# MSP432E411Y register map
Vendor: Texas Instruments; File version: 3.200
CPU: CM4 r1p2, little endian, no MPU, no FPU, 0x3 interrupt priority bits, 0x0 interrupts
Registers are 32-bit, read-write, no defined reset value unless marked. A register's access mark holds for its fields unless they carry their own. Offsets are from the block's base; [hi:lo] are bit positions; {n}, {i} and the like mark numbered series.

## TIMER0 — Register map for TIMER0 peripheral
Base 0x40030000; register names take the prefix TIMER0
0x00 CFG — GPTM Configuration
  [2:0] TIMER_CFG
    0=TIMER_CFG_32_BIT_TIMER (For a 16/32-bit timer, this value selects the 32-bit timer configuration); 1=TIMER_CFG_32_BIT_RTC (For a 16/32-bit timer, this value selects the 32-bit real-time clock (RTC) counter configuration); 4=TIMER_CFG_16_BIT (For a 16/32-bit timer, this value selects the 16-bit timer configuration)
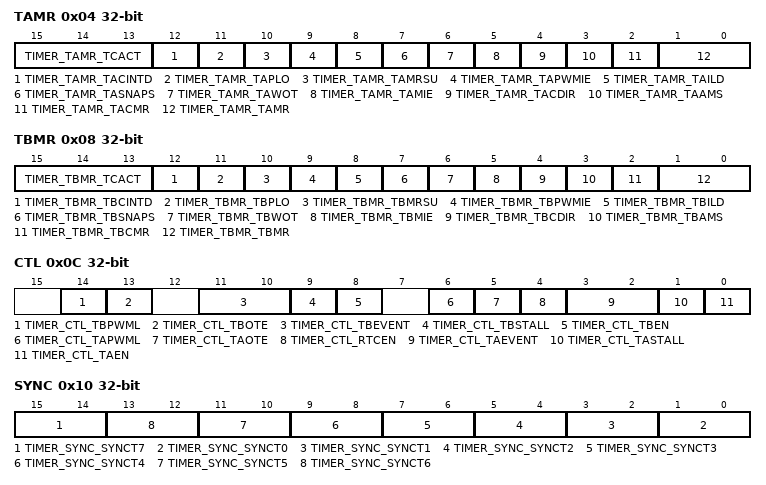
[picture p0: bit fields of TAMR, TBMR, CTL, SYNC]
0x04 TAMR — GPTM Timer A Mode
  [15:13] TIMER_TAMR_TCACT — Timer Compare Action Select
    0=TIMER_TAMR_TCACT_NONE (Disable compare operations); 1=TIMER_TAMR_TCACT_TOGGLE (Toggle State on Time-Out); 2=TIMER_TAMR_TCACT_CLRTO (Clear CCP on Time-Out); 3=TIMER_TAMR_TCACT_SETTO (Set CCP on Time-Out); 4=TIMER_TAMR_TCACT_SETTOGTO (Set CCP immediately and toggle on Time-Out); 5=TIMER_TAMR_TCACT_CLRTOGTO (Clear CCP immediately and toggle on Time-Out); 6=TIMER_TAMR_TCACT_SETCLRTO (Set CCP immediately and clear on Time-Out); 7=TIMER_TAMR_TCACT_CLRSETTO (Clear CCP immediately and set on Time-Out)
  [12] TIMER_TAMR_TACINTD — One-shot/Periodic Interrupt Disable
  [11] TIMER_TAMR_TAPLO — GPTM Timer A PWM Legacy Operation
  [10] TIMER_TAMR_TAMRSU — GPTM Timer A Match Register Update
  [9] TIMER_TAMR_TAPWMIE — GPTM Timer A PWM Interrupt Enable
  [8] TIMER_TAMR_TAILD — GPTM Timer A Interval Load Write
  [7] TIMER_TAMR_TASNAPS — GPTM Timer A Snap-Shot Mode
  [6] TIMER_TAMR_TAWOT — GPTM Timer A Wait-on-Trigger
  [5] TIMER_TAMR_TAMIE — GPTM Timer A Match Interrupt Enable
  [4] TIMER_TAMR_TACDIR — GPTM Timer A Count Direction
  [3] TIMER_TAMR_TAAMS — GPTM Timer A Alternate Mode Select
  [2] TIMER_TAMR_TACMR — GPTM Timer A Capture Mode
  [1:0] TIMER_TAMR_TAMR — GPTM Timer A Mode
    1=TIMER_TAMR_TAMR_1_SHOT (One-Shot Timer mode); 2=TIMER_TAMR_TAMR_PERIOD (Periodic Timer mode); 3=TIMER_TAMR_TAMR_CAP (Capture mode)
0x08 TBMR — GPTM Timer B Mode
  [15:13] TIMER_TBMR_TCACT — Timer Compare Action Select
    0=TIMER_TBMR_TCACT_NONE (Disable compare operations); 1=TIMER_TBMR_TCACT_TOGGLE (Toggle State on Time-Out); 2=TIMER_TBMR_TCACT_CLRTO (Clear CCP on Time-Out); 3=TIMER_TBMR_TCACT_SETTO (Set CCP on Time-Out); 4=TIMER_TBMR_TCACT_SETTOGTO (Set CCP immediately and toggle on Time-Out); 5=TIMER_TBMR_TCACT_CLRTOGTO (Clear CCP immediately and toggle on Time-Out); 6=TIMER_TBMR_TCACT_SETCLRTO (Set CCP immediately and clear on Time-Out); 7=TIMER_TBMR_TCACT_CLRSETTO (Clear CCP immediately and set on Time-Out)
  [12] TIMER_TBMR_TBCINTD — One-Shot/Periodic Interrupt Disable
  [11] TIMER_TBMR_TBPLO — GPTM Timer B PWM Legacy Operation
  [10] TIMER_TBMR_TBMRSU — GPTM Timer B Match Register Update
  [9] TIMER_TBMR_TBPWMIE — GPTM Timer B PWM Interrupt Enable
  [8] TIMER_TBMR_TBILD — GPTM Timer B Interval Load Write
  [7] TIMER_TBMR_TBSNAPS — GPTM Timer B Snap-Shot Mode
  [6] TIMER_TBMR_TBWOT — GPTM Timer B Wait-on-Trigger
  [5] TIMER_TBMR_TBMIE — GPTM Timer B Match Interrupt Enable
  [4] TIMER_TBMR_TBCDIR — GPTM Timer B Count Direction
  [3] TIMER_TBMR_TBAMS — GPTM Timer B Alternate Mode Select
  [2] TIMER_TBMR_TBCMR — GPTM Timer B Capture Mode
  [1:0] TIMER_TBMR_TBMR — GPTM Timer B Mode
    1=TIMER_TBMR_TBMR_1_SHOT (One-Shot Timer mode); 2=TIMER_TBMR_TBMR_PERIOD (Periodic Timer mode); 3=TIMER_TBMR_TBMR_CAP (Capture mode)
0x0C CTL — GPTM Control
  [14] TIMER_CTL_TBPWML — GPTM Timer B PWM Output Level
  [13] TIMER_CTL_TBOTE — GPTM Timer B Output Trigger Enable
  [11:10] TIMER_CTL_TBEVENT — GPTM Timer B Event Mode
    0=TIMER_CTL_TBEVENT_POS (Positive edge); 1=TIMER_CTL_TBEVENT_NEG (Negative edge); 3=TIMER_CTL_TBEVENT_BOTH (Both edges)
  [9] TIMER_CTL_TBSTALL — GPTM Timer B Stall Enable
  [8] TIMER_CTL_TBEN — GPTM Timer B Enable
  [6] TIMER_CTL_TAPWML — GPTM Timer A PWM Output Level
  [5] TIMER_CTL_TAOTE — GPTM Timer A Output Trigger Enable
  [4] TIMER_CTL_RTCEN — GPTM RTC Stall Enable
  [3:2] TIMER_CTL_TAEVENT — GPTM Timer A Event Mode
    0=TIMER_CTL_TAEVENT_POS (Positive edge); 1=TIMER_CTL_TAEVENT_NEG (Negative edge); 3=TIMER_CTL_TAEVENT_BOTH (Both edges)
  [1] TIMER_CTL_TASTALL — GPTM Timer A Stall Enable
  [0] TIMER_CTL_TAEN — GPTM Timer A Enable
0x10 SYNC — GPTM Synchronize
  [15:14] TIMER_SYNC_SYNCT7 — Synchronize GPTM Timer 7
    0=TIMER_SYNC_SYNCT7_NONE (GPT7 is not affected); 1=TIMER_SYNC_SYNCT7_TA (A timeout event for Timer A of GPTM7 is triggered); 2=TIMER_SYNC_SYNCT7_TB (A timeout event for Timer B of GPTM7 is triggered); 3=TIMER_SYNC_SYNCT7_TATB (A timeout event for both Timer A and Timer B of GPTM7 is triggered)
  [2n+1:2n] TIMER_SYNC_SYNCT{n} (n=0..6) — Synchronize GPTM Timer {n}
    0=TIMER_SYNC_SYNCT{n}_NONE (GPTM{n} is not affected); 1=TIMER_SYNC_SYNCT{n}_TA (A timeout event for Timer A of GPTM{n} is triggered); 2=TIMER_SYNC_SYNCT{n}_TB (A timeout event for Timer B of GPTM{n} is triggered); 3=TIMER_SYNC_SYNCT{n}_TATB (A timeout event for both Timer A and Timer B of GPTM{n} is triggered)
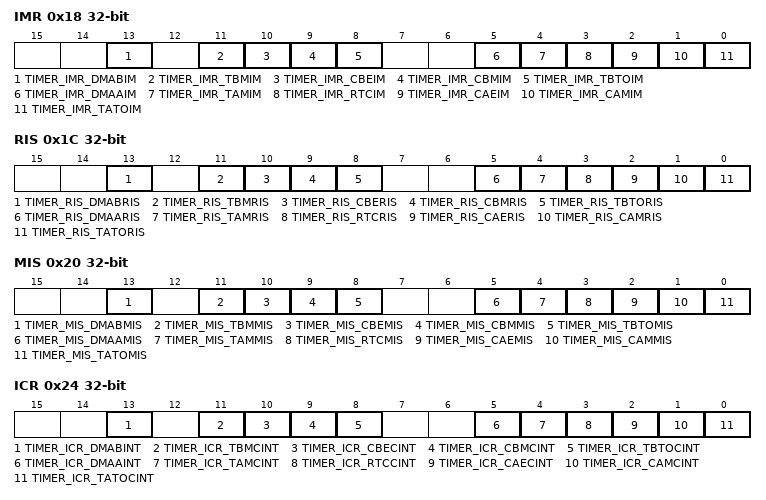
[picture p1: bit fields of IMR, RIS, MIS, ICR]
0x18 IMR — GPTM Interrupt Mask
  [13] TIMER_IMR_DMABIM — GPTM Timer B DMA Done Interrupt Mask
  [11] TIMER_IMR_TBMIM — GPTM Timer B Match Interrupt Mask
  [10] TIMER_IMR_CBEIM — GPTM Timer B Capture Mode Event Interrupt Mask
  [9] TIMER_IMR_CBMIM — GPTM Timer B Capture Mode Match Interrupt Mask
  [8] TIMER_IMR_TBTOIM — GPTM Timer B Time-Out Interrupt Mask
  [5] TIMER_IMR_DMAAIM — GPTM Timer A DMA Done Interrupt Mask
  [4] TIMER_IMR_TAMIM — GPTM Timer A Match Interrupt Mask
  [3] TIMER_IMR_RTCIM — GPTM RTC Interrupt Mask
  [2] TIMER_IMR_CAEIM — GPTM Timer A Capture Mode Event Interrupt Mask
  [1] TIMER_IMR_CAMIM — GPTM Timer A Capture Mode Match Interrupt Mask
  [0] TIMER_IMR_TATOIM — GPTM Timer A Time-Out Interrupt Mask
0x1C RIS — GPTM Raw Interrupt Status
  [13] TIMER_RIS_DMABRIS — GPTM Timer B DMA Done Raw Interrupt Status
  [11] TIMER_RIS_TBMRIS — GPTM Timer B Match Raw Interrupt
  [10] TIMER_RIS_CBERIS — GPTM Timer B Capture Mode Event Raw Interrupt
  [9] TIMER_RIS_CBMRIS — GPTM Timer B Capture Mode Match Raw Interrupt
  [8] TIMER_RIS_TBTORIS — GPTM Timer B Time-Out Raw Interrupt
  [5] TIMER_RIS_DMAARIS — GPTM Timer A DMA Done Raw Interrupt Status
  [4] TIMER_RIS_TAMRIS — GPTM Timer A Match Raw Interrupt
  [3] TIMER_RIS_RTCRIS — GPTM RTC Raw Interrupt
  [2] TIMER_RIS_CAERIS — GPTM Timer A Capture Mode Event Raw Interrupt
  [1] TIMER_RIS_CAMRIS — GPTM Timer A Capture Mode Match Raw Interrupt
  [0] TIMER_RIS_TATORIS — GPTM Timer A Time-Out Raw Interrupt
0x20 MIS — GPTM Masked Interrupt Status
  [13] TIMER_MIS_DMABMIS — GPTM Timer B DMA Done Masked Interrupt
  [11] TIMER_MIS_TBMMIS — GPTM Timer B Match Masked Interrupt
  [10] TIMER_MIS_CBEMIS — GPTM Timer B Capture Mode Event Masked Interrupt
  [9] TIMER_MIS_CBMMIS — GPTM Timer B Capture Mode Match Masked Interrupt
  [8] TIMER_MIS_TBTOMIS — GPTM Timer B Time-Out Masked Interrupt
  [5] TIMER_MIS_DMAAMIS — GPTM Timer A DMA Done Masked Interrupt
  [4] TIMER_MIS_TAMMIS — GPTM Timer A Match Masked Interrupt
  [3] TIMER_MIS_RTCMIS — GPTM RTC Masked Interrupt
  [2] TIMER_MIS_CAEMIS — GPTM Timer A Capture Mode Event Masked Interrupt
  [1] TIMER_MIS_CAMMIS — GPTM Timer A Capture Mode Match Masked Interrupt
  [0] TIMER_MIS_TATOMIS — GPTM Timer A Time-Out Masked Interrupt
0x24 ICR wo — GPTM Interrupt Clear
  [13] TIMER_ICR_DMABINT — GPTM Timer B DMA Done Interrupt Clear
  [11] TIMER_ICR_TBMCINT — GPTM Timer B Match Interrupt Clear
  [10] TIMER_ICR_CBECINT — GPTM Timer B Capture Mode Event Interrupt Clear
  [9] TIMER_ICR_CBMCINT — GPTM Timer B Capture Mode Match Interrupt Clear
  [8] TIMER_ICR_TBTOCINT — GPTM Timer B Time-Out Interrupt Clear
  [5] TIMER_ICR_DMAAINT — GPTM Timer A DMA Done Interrupt Clear
  [4] TIMER_ICR_TAMCINT — GPTM Timer A Match Interrupt Clear
  [3] TIMER_ICR_RTCCINT — GPTM RTC Interrupt Clear
  [2] TIMER_ICR_CAECINT — GPTM Timer A Capture Mode Event Interrupt Clear
  [1] TIMER_ICR_CAMCINT — GPTM Timer A Capture Mode Match Interrupt Clear
  [0] TIMER_ICR_TATOCINT — GPTM Timer A Time-Out Raw Interrupt
0x28 TAILR — GPTM Timer A Interval Load
0x2C TBILR — GPTM Timer B Interval Load
0x30 TAMATCHR — GPTM Timer A Match
0x34 TBMATCHR — GPTM Timer B Match
0x38 TAPR — GPTM Timer A Prescale
  [7:0] TIMER_TAPR_TAPSR
0x3C TBPR — GPTM Timer B Prescale
  [7:0] TIMER_TBPR_TBPSR
0x40 TAPMR — GPTM TimerA Prescale Match
  [7:0] TIMER_TAPMR_TAPSMR
0x44 TBPMR — GPTM TimerB Prescale Match
  [7:0] TIMER_TBPMR_TBPSMR
0x48 TAR — GPTM Timer A
0x4C TBR — GPTM Timer B
0x50 TAV — GPTM Timer A Value
0x54 TBV — GPTM Timer B Value
0x58 RTCPD — GPTM RTC Predivide
  [15:0] TIMER_RTCPD_RTCPD — RTC Predivide Counter Value
0x5C TAPS — GPTM Timer A Prescale Snapshot
  [15:0] TIMER_TAPS_PSS — GPTM Timer A Prescaler Snapshot
0x60 TBPS — GPTM Timer B Prescale Snapshot
  [15:0] TIMER_TBPS_PSS — GPTM Timer A Prescaler Value
0x64 TAPV — GPTM Timer A Prescale Value
0x68 TBPV — GPTM Timer B Prescale Value
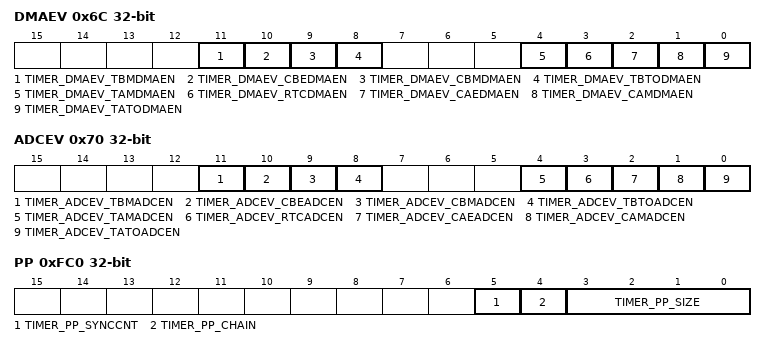
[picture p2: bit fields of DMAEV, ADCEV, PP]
0x6C DMAEV — GPTM DMA Event
  [11] TIMER_DMAEV_TBMDMAEN — GPTM B Mode Match Event DMA Trigger Enable
  [10] TIMER_DMAEV_CBEDMAEN — GPTM B Capture Event DMA Trigger Enable
  [9] TIMER_DMAEV_CBMDMAEN — GPTM B Capture Match Event DMA Trigger Enable
  [8] TIMER_DMAEV_TBTODMAEN — GPTM B Time-Out Event DMA Trigger Enable
  [4] TIMER_DMAEV_TAMDMAEN — GPTM A Mode Match Event DMA Trigger Enable
  [3] TIMER_DMAEV_RTCDMAEN — GPTM A RTC Match Event DMA Trigger Enable
  [2] TIMER_DMAEV_CAEDMAEN — GPTM A Capture Event DMA Trigger Enable
  [1] TIMER_DMAEV_CAMDMAEN — GPTM A Capture Match Event DMA Trigger Enable
  [0] TIMER_DMAEV_TATODMAEN — GPTM A Time-Out Event DMA Trigger Enable
0x70 ADCEV — GPTM ADC Event
  [11] TIMER_ADCEV_TBMADCEN — GPTM B Mode Match Event ADC Trigger Enable
  [10] TIMER_ADCEV_CBEADCEN — GPTM B Capture Event ADC Trigger Enable
  [9] TIMER_ADCEV_CBMADCEN — GPTM B Capture Match Event ADC Trigger Enable
  [8] TIMER_ADCEV_TBTOADCEN — GPTM B Time-Out Event ADC Trigger Enable
  [4] TIMER_ADCEV_TAMADCEN — GPTM A Mode Match Event ADC Trigger Enable
  [3] TIMER_ADCEV_RTCADCEN — GPTM RTC Match Event ADC Trigger Enable
  [2] TIMER_ADCEV_CAEADCEN — GPTM A Capture Event ADC Trigger Enable
  [1] TIMER_ADCEV_CAMADCEN — GPTM A Capture Match Event ADC Trigger Enable
  [0] TIMER_ADCEV_TATOADCEN — GPTM A Time-Out Event ADC Trigger Enable
0xFC0 PP — GPTM Peripheral Properties
  [5] TIMER_PP_SYNCCNT — Synchronize Start
  [4] TIMER_PP_CHAIN — Chain with Other Timers
  [3:0] TIMER_PP_SIZE — Count Size
    0=Timer A and Timer B counters are 16 bits each with an 8-bit prescale counter; 1=Timer A and Timer B counters are 32 bits each with a 16-bit prescale counter

## TIMER1 — Register map for TIMER0 peripheral
Base 0x40031000; register names take the prefix TIMER1
Registers as TIMER0.

## TIMER2 — Register map for TIMER0 peripheral
Base 0x40032000; register names take the prefix TIMER2
Registers as TIMER0.

## TIMER3 — Register map for TIMER0 peripheral
Base 0x40033000; register names take the prefix TIMER3
Registers as TIMER0.

## TIMER4 — Register map for TIMER0 peripheral
Base 0x40034000; register names take the prefix TIMER4
Registers as TIMER0.

## TIMER5 — Register map for TIMER0 peripheral
Base 0x40035000; register names take the prefix TIMER5
Registers as TIMER0.

## TIMER6 — Register map for TIMER0 peripheral
Base 0x400E0000; register names take the prefix TIMER6
Registers as TIMER0.

## TIMER7 — Register map for TIMER0 peripheral
Base 0x400E1000; register names take the prefix TIMER7
Registers as TIMER0.
